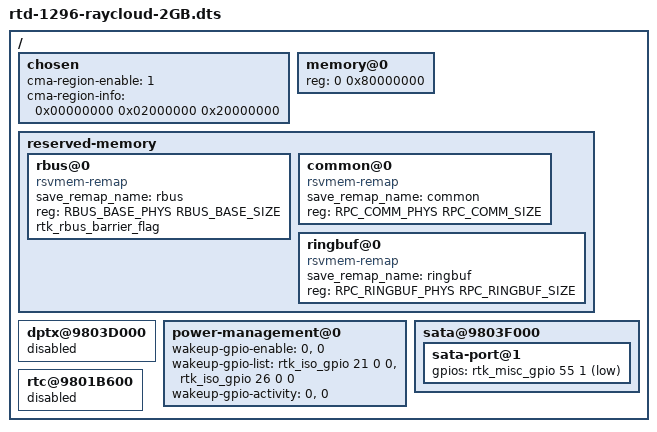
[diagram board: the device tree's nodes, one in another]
/dts-v1/;
#include <dt-bindings/soc/rtd129x,memory.h>

/memreserve/ SYS_BOOTCODE_MEMBASE SYS_BOOTCODE_MEMSIZE;
/memreserve/ RPC_COMM_PHYS RPC_COMM_SIZE ;
/memreserve/ RPC_RINGBUF_PHYS RPC_RINGBUF_SIZE;
/memreserve/ ROOTFS_NORMAL_START ROOTFS_NORMAL_SIZE;
/memreserve/ ACPU_IDMEM_PHYS ACPU_IDMEM_SIZE;

#include "rtd-1296.dtsi"
#include "rtd-1296-saola-common.dtsi"

/ {

	/*
	 * NOTE:
	 * <flag size base>
	 * flag: reserved
	 * size: unit is byte
	 * base: unit is byte
	 *
	 * Array size not over 8;
	 * You may change the max array size in KConfig,
	 * max CMA array size is CONFIG_CMA_AREAS+1.
	 *
	 * If cma-region-enable is enabled<1>,
	 * kernel driver will use cma-region-info to initial CMA memory.
	 *
	 * If cma-region-enable is disabled<0>,
	 * kernel driver will use cma= to initial CMA memory.
	 *
	 * if both setting is loaded, cma-region-info had higher priority.
	 */
	chosen {
		cma-region-enable = <1>;
		cma-region-info = <0x00000000 0x02000000 0x20000000>;
		/*cma-region-info = <0x00000000 0x01000000 0x12c00000>,
			<0x00000000 0x12c00000 0x20000000>;*/
	};

	memory@0 {
		device_type = "memory";
		reg = <0 0x80000000>; /* 2048 MB */
	};

	reserved-memory {
		#address-cells = <1>;
		#size-cells = <1>;
		ranges;

		rbus@0 {
			compatible = "rsvmem-remap";
			save_remap_name = "rbus";
			reg = <RBUS_BASE_PHYS RBUS_BASE_SIZE>;
			rtk_rbus_barrier_flag;
		};

		common@0 {
			compatible = "rsvmem-remap";
			save_remap_name = "common";
			reg = <RPC_COMM_PHYS RPC_COMM_SIZE>;
		};

		ringbuf@0 {
			compatible = "rsvmem-remap";
			save_remap_name = "ringbuf";
			reg = <RPC_RINGBUF_PHYS RPC_RINGBUF_SIZE>;
		};
	};

	dptx@9803D000 {
		status = "disabled";
	};

	power-management@0 {
		wakeup-gpio-enable = <0>, <0>;
		wakeup-gpio-list = <&rtk_iso_gpio 21 0 0>,
			<&rtk_iso_gpio 26 0 0>;
		wakeup-gpio-activity =<0>, <0>;
	};

	sata@9803F000 {
		sata-port@1 {
			gpios = <&rtk_misc_gpio 55 1 1>;
		};
	};

	rtc@9801B600 {
		status = "disabled";
	};
};

